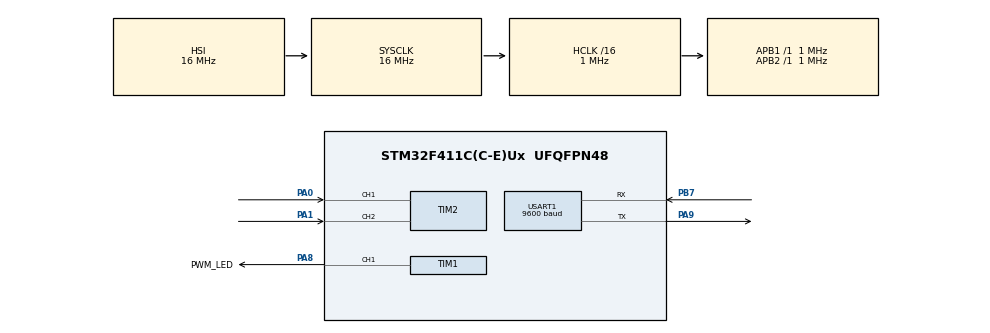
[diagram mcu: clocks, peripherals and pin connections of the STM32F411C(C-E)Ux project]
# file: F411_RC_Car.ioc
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Mcu.Family=STM32F4
Mcu.Name=STM32F411C(C-E)Ux
Mcu.Package=UFQFPN48
NVIC.PriorityGroup=NVIC_PRIORITYGROUP_4
NVIC.TIM2_IRQn=true\:0\:0\:false\:false\:true\:true\:true\:true
PA0-WKUP.Signal=S_TIM2_CH1_ETR
PA1.Signal=S_TIM2_CH2
PA13.Mode=Trace_Asynchronous_SW
PA13.Signal=SYS_JTMS-SWDIO
PA14.Mode=Trace_Asynchronous_SW
PA14.Signal=SYS_JTCK-SWCLK
PA8.GPIO_Label=PWM_LED
PA8.Signal=S_TIM1_CH1
PA9.Mode=Asynchronous
PA9.Signal=USART1_TX
PB3.Mode=Trace_Asynchronous_SW
PB3.Signal=SYS_JTDO-SWO
PB7.Mode=Asynchronous
PB7.Signal=USART1_RX
PH0\ -\ OSC_IN.Mode=HSE-External-Oscillator
PH0\ -\ OSC_IN.Signal=RCC_OSC_IN
PH1\ -\ OSC_OUT.Mode=HSE-External-Oscillator
PH1\ -\ OSC_OUT.Signal=RCC_OSC_OUT
ProjectManager.HeapSize=0x200
ProjectManager.StackSize=0x400
ProjectManager.TargetToolchain=STM32CubeIDE
RCC.48MHZClocksFreq_Value=50000000
RCC.AHBCLKDivider=RCC_SYSCLK_DIV16
RCC.AHBFreq_Value=1000000
RCC.APB1Freq_Value=1000000
RCC.APB1TimFreq_Value=1000000
RCC.APB2Freq_Value=1000000
RCC.APB2TimFreq_Value=1000000
RCC.CortexFreq_Value=1000000
RCC.HCLKFreq_Value=1000000
RCC.HSE_VALUE=25000000
RCC.HSI_VALUE=16000000
RCC.LSE_VALUE=32768
RCC.PLLM=8
RCC.PLLN=100
RCC.SYSCLKFreq_VALUE=16000000
RCC.VCOOutputFreq_Value=200000000
SH.S_TIM1_CH1.0=TIM1_CH1,PWM Generation1 CH1
SH.S_TIM2_CH1_ETR.0=TIM2_CH1,Input_Capture1_from_TI1
SH.S_TIM2_CH2.0=TIM2_CH2,Input_Capture2_from_TI2
TIM1.Channel-PWM\ Generation1\ CH1=TIM_CHANNEL_1
TIM1.Period=1000
TIM1.Prescaler=0
TIM2.Channel-Input_Capture1_from_TI1=TIM_CHANNEL_1
TIM2.Channel-Input_Capture2_from_TI2=TIM_CHANNEL_2
USART1.BaudRate=9600
USART1.VirtualMode=VM_ASYNC
VP_TIM1_VS_ClockSourceINT.Mode=Internal
board=custom

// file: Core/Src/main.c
/* USER CODE BEGIN Header */
/**
  ******************************************************************************
  * @file           : main.c
  * @brief          : Main program body
  ******************************************************************************
  * @attention
  *
  * Copyright (c) 2024 STMicroelectronics.
  * All rights reserved.
  *
  * This software is licensed under terms that can be found in the LICENSE file
  * in the root directory of this software component.
  * If no LICENSE file comes with this software, it is provided AS-IS.
  *
  ******************************************************************************
  */
/* USER CODE END Header */
#include "main.h"
#include "tim.h"
#include "usart.h"
#include "gpio.h"

/* USER CODE BEGIN Includes */
#include "switches.h"
#include "Logger.h"
#include "PWM_control.h"
#include <stdio.h>
/* USER CODE END Includes */

void SystemClock_Config(void);

int main(void)
{

  /* MCU Configuration--------------------------------------------------------*/

  /* Reset of all peripherals, Initializes the Flash interface and the Systick. */
  HAL_Init();

  /* Configure the system clock */
  SystemClock_Config();

  /* Initialize all configured peripherals */
  MX_GPIO_Init();
  MX_TIM2_Init();
  MX_TIM1_Init();
  MX_USART1_UART_Init();
  /* USER CODE BEGIN 2 */
#ifdef DEBUG_MSG
  Log("RC Control started\r\n");
#endif  // DEBUG_MSG

  PWM_Control_Init();

  /* USER CODE END 2 */

  /* Infinite loop */
  /* USER CODE BEGIN WHILE */
  while (1)
  {

	  PWM_Control_Process();
	  HAL_Delay(1);

    /* USER CODE END WHILE */

  }
}

void SystemClock_Config(void)
{
  RCC_OscInitTypeDef RCC_OscInitStruct = {0};
  RCC_ClkInitTypeDef RCC_ClkInitStruct = {0};

  /** Configure the main internal regulator output voltage
  */
  __HAL_RCC_PWR_CLK_ENABLE();
  __HAL_PWR_VOLTAGESCALING_CONFIG(PWR_REGULATOR_VOLTAGE_SCALE1);

  /** Initializes the RCC Oscillators according to the specified parameters
  * in the RCC_OscInitTypeDef structure.
  */
  RCC_OscInitStruct.OscillatorType = RCC_OSCILLATORTYPE_HSI;
  RCC_OscInitStruct.HSIState = RCC_HSI_ON;
  RCC_OscInitStruct.HSICalibrationValue = RCC_HSICALIBRATION_DEFAULT;
  RCC_OscInitStruct.PLL.PLLState = RCC_PLL_NONE;
  if (HAL_RCC_OscConfig(&RCC_OscInitStruct) != HAL_OK)
  {
    Error_Handler();
  }

  /** Initializes the CPU, AHB and APB buses clocks
  */
  RCC_ClkInitStruct.ClockType = RCC_CLOCKTYPE_HCLK|RCC_CLOCKTYPE_SYSCLK
                              |RCC_CLOCKTYPE_PCLK1|RCC_CLOCKTYPE_PCLK2;
  RCC_ClkInitStruct.SYSCLKSource = RCC_SYSCLKSOURCE_HSI;
  RCC_ClkInitStruct.AHBCLKDivider = RCC_SYSCLK_DIV16;
  RCC_ClkInitStruct.APB1CLKDivider = RCC_HCLK_DIV1;
  RCC_ClkInitStruct.APB2CLKDivider = RCC_HCLK_DIV1;

  if (HAL_RCC_ClockConfig(&RCC_ClkInitStruct, FLASH_LATENCY_0) != HAL_OK)
  {
    Error_Handler();
  }
}

void Error_Handler(void)
{
  __disable_irq();
  while (1)
  {
  }
}
